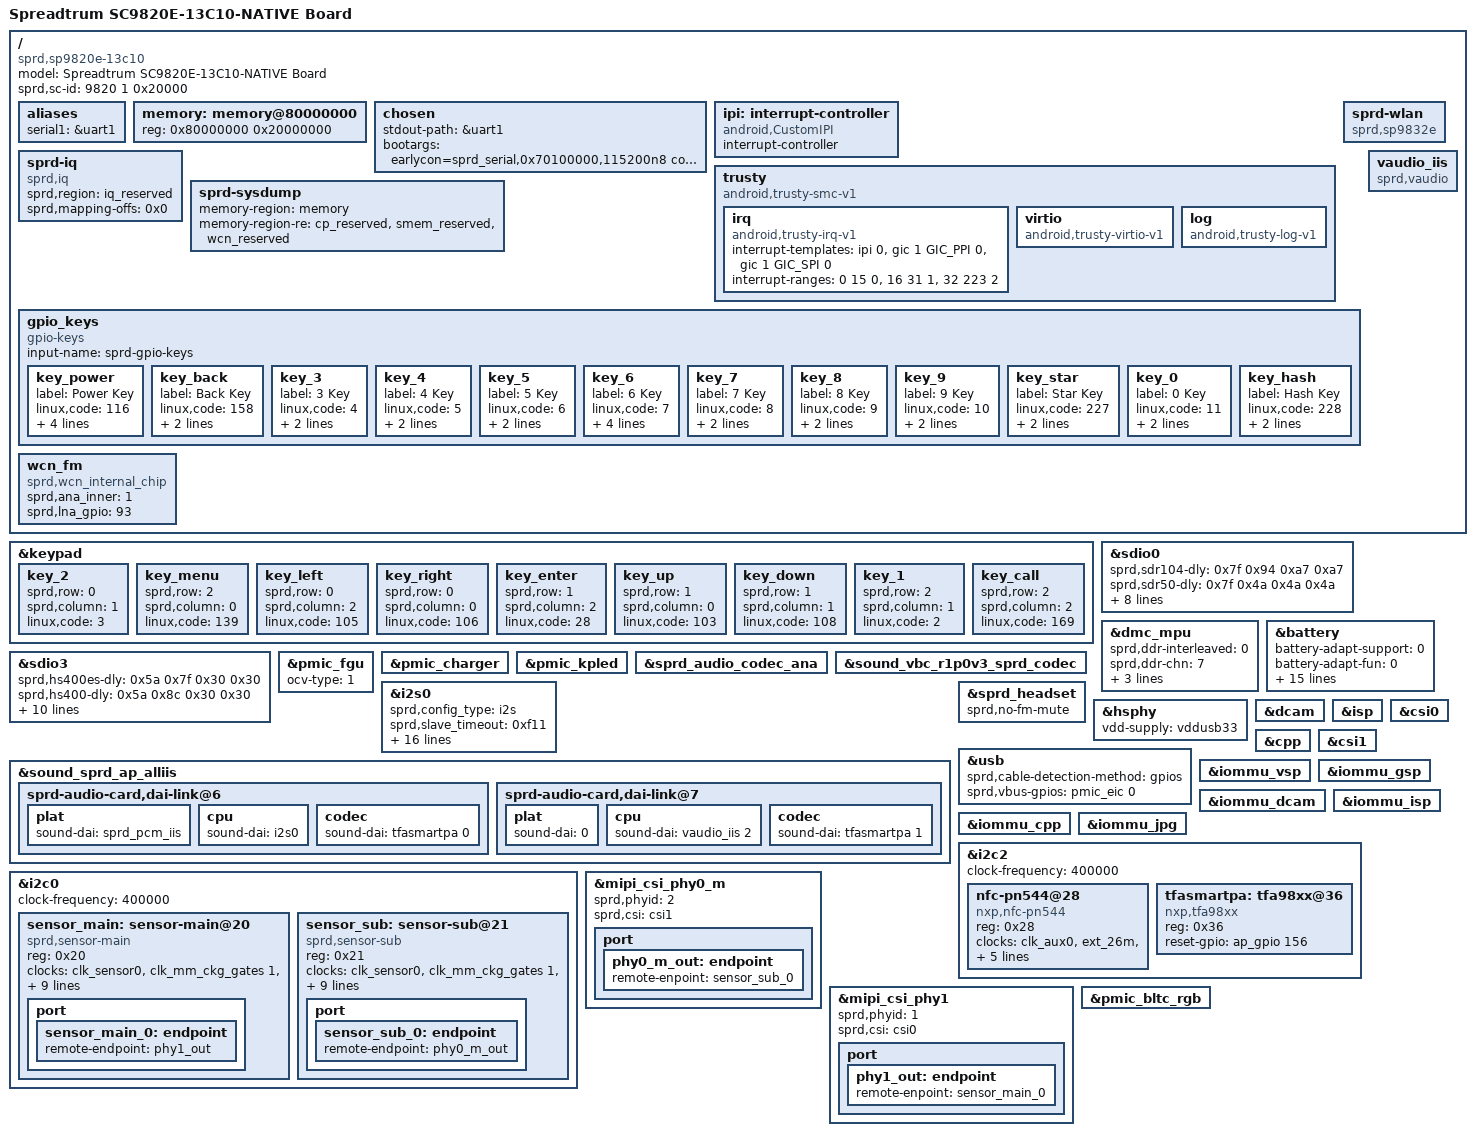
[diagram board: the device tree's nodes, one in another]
/*
 * Spreadtrum sharkle sp9820e board DTS file
 *
 * Copyright (C) 2017, Spreadtrum Communications Inc.
 *
 * This file is licensed under a dual GPLv2 or X11 license.
 */
/dts-v1/;

#include "sc9820e.dtsi"
#include "sp9820e-common.dtsi"

/ {
	model = "Spreadtrum SC9820E-13C10-NATIVE Board";

	compatible = "sprd,sp9820e-13c10", "sprd,sc9820e";

	sprd,sc-id = <9820 1 0x20000>;

	aliases {
		serial1 = &uart1;
	};

	memory: memory@80000000 {
		device_type = "memory";
		reg = <0x80000000 0x20000000>;
	};

	chosen {
		stdout-path = &uart1;
		bootargs = "earlycon=sprd_serial,0x70100000,115200n8 console=ttyS1,115200n8 loglevel=1 init=/init root=/dev/ram0 rw androidboot.hardware=sp9820e_13c10";
	};

	ipi: interrupt-controller {
		compatible = "android,CustomIPI";
		#interrupt-cells = <1>;
		interrupt-controller;
	};

	trusty {
		compatible = "android,trusty-smc-v1";

		irq {
			compatible = "android,trusty-irq-v1";
			interrupt-templates = <&ipi 0>,
						<&gic 1 GIC_PPI 0>,
						<&gic 1 GIC_SPI 0>;
			interrupt-ranges = < 0  15 0>,
						<16  31 1>,
						<32 223 2>;
		};

		virtio {
			compatible = "android,trusty-virtio-v1";
		};

		log {
			compatible = "android,trusty-log-v1";
		};
	};

	sprd-iq {
		compatible = "sprd,iq";
		sprd,region = <&iq_reserved>;
		sprd,mapping-offs = <0x0>;
	};

	sprd-sysdump {
		memory-region = <&memory>;
		memory-region-re = <&cp_reserved>, <&smem_reserved>,
				   <&wcn_reserved>;
	};

	sprd-wlan {
		 compatible = "sprd,sp9832e";
	};

	gpio_keys {
		compatible = "gpio-keys";
		input-name = "sprd-gpio-keys";
		status = "ok";

		key_power {
			label = "Power Key";
			linux,code = <116>;
			gpios = <&pmic_eic 1 1>;
			debounce-interval = <5>;
			gpio-key,wakeup;
			gpio-key,level-trigger;
		};
		key_back {
			label = "Back Key";
			linux,code = <158>;
			gpios = <&ap_gpio 32 1>;
			gpio-key,wakeup;
		};
		key_3 {
			label = "3 Key";
			linux,code = <4>;
			gpios = <&ap_gpio 91 1>;
			gpio-key,wakeup;
		};
		key_4 {
			label = "4 Key";
			linux,code = <5>;
			gpios = <&ap_gpio 92 1>;
			gpio-key,wakeup;
		};
		key_5 {
			label = "5 Key";
			linux,code = <6>;
			gpios = <&ap_gpio 144 1>;
			gpio-key,wakeup;
		};
		key_6 {
			label = "6 Key";
			linux,code = <7>;
			gpios = <&pmic_eic 10 0>;
			debounce-interval = <5>;
			gpio-key,wakeup;
			gpio-key,level-trigger;
		};
		key_7 {
			label = "7 Key";
			linux,code = <8>;
			gpios = <&ap_gpio 146 1>;
			gpio-key,wakeup;
		};
		key_8 {
			label = "8 Key";
			linux,code = <9>;
			gpios = <&ap_gpio 90 1>;
			gpio-key,wakeup;
		};
		key_9 {
			label = "9 Key";
			linux,code = <10>;
			gpios = <&ap_gpio 147 1>;
			gpio-key,wakeup;
		};
		key_star {
			label = "Star Key";
			linux,code = <227>;
			gpios = <&ap_gpio 88 1>;
			gpio-key,wakeup;
		};
		key_0 {
			label = "0 Key";
			linux,code = <11>;
			gpios = <&ap_gpio 85 1>;
			gpio-key,wakeup;
		};
		key_hash {
			label = "Hash Key";
			linux,code = <228>;
			gpios = <&ap_gpio 154 1>;
			gpio-key,wakeup;
		};
	};

	vaudio_iis: vaudio_iis {
		compatible = "sprd,vaudio";
		#sound-dai-cells = <1>;
	};

	wcn_fm {
			compatible = "sprd,wcn_internal_chip";
			sprd,ana_inner = <1>;
			sprd,lna_gpio = <93>;
	};
};

&keypad {
	status = "okay";
	key_2 {
		sprd,row = <0>;
		sprd,column = <1>;
		linux,code = <3>;
	};
	key_menu {
		sprd,row = <2>;
		sprd,column = <0>;
		linux,code = <139>;
	};
	key_left {
		sprd,row = <0>;
		sprd,column = <2>;
		linux,code = <105>;
	};
	key_right {
		sprd,row = <0>;
		sprd,column = <0>;
		linux,code = <106>;
	};
	key_enter {
		sprd,row = <1>;
		sprd,column = <2>;
		linux,code = <28>;
	};
	key_up {
		sprd,row = <1>;
		sprd,column = <0>;
		linux,code = <103>;
	};
	key_down {
		sprd,row = <1>;
		sprd,column = <1>;
		linux,code = <108>;
	};
	key_1 {
		sprd,row = <2>;
		sprd,column = <1>;
		linux,code = <2>;
	};
	key_call {
		sprd,row = <2>;
		sprd,column = <2>;
		linux,code = <169>;
	};
};

&sdio0 {
	sprd,sdr104-dly = <0x7f 0x94 0xa7 0xa7>;
	sprd,sdr50-dly = <0x7f 0x4a 0x4a 0x4a>;
	vmmc-supply = <&vddsdcore>;
	vqmmc-supply = <&vddsdio>;
	voltage-ranges = <3000 3000>;
	bus-width = <4>;
	sd-uhs-sdr50;
	sprd,name = "sdio_sd";
	no-sdio;
	no-mmc;
	status = "okay";
};

&dmc_mpu {
	sprd,ddr-interleaved = <0>;
	sprd,ddr-chn = <7>;
	chn-name = "MM", "GPU", "DISP",
		"A53", "AP/VSP/GSP", "WTLCP/PUBCP",
		"WCN/AON";
	memory-region = <&pub0_mpu_reserved>;
};

&sdio3 {
	sprd,hs400es-dly = <0x5a 0x7f 0x30 0x30>;
	sprd,hs400-dly = <0x5a 0x8c 0x30 0x30>;
	sprd,hs200-dly = <0x7f 0x8c 0x8e 0x8e>;
	sprd,ddr52-dly = <0x9f 0xB3 0x1e 0x1e>;
	vmmc-supply = <&vddemmccore>;
	voltage-ranges = <3000 3000>;
	bus-width = <8>;
	non-removable;
	cap-mmc-hw-reset;
	sprd,name = "sdio_emmc";
	no-sdio;
	no-sd;
	status = "okay";
};

&battery {
	battery-adapt-support = <0>;
	battery-adapt-fun = <0>;
	adp-cdp-cur = <450>;
	adp-dcp-cur = <700>;
	adp-sdp-cur = <450>;
	adp-unknown-cur = <450>;
	chg-end-vol = <4200>;
	chg-end-vol-check = <4180>;
	chg-bat-safety-vol = <4230>;
	rechg-vol = <4120>;
	rsense-real = <200>;
	rint = <206>;
	cnom = <1962>;
	ocv-tab-vol = <4172 4102 4055 4009 3973 3942 3912
			3885 3856 3822 3798 3784 3776 3772
			3768 3760 3742 3714 3666 3599 3400>;
	ocv-tab-cap = <100  95   90   85   80   75   70
			65   60   55   50   45   40   35
			30   25   20   15   10   5   0>;
};

&pmic_fgu {
	ocv-type = <1>;
};

&pmic_charger {
	status = "okay";
};

&pmic_kpled {
	 status = "okay";
};

&sprd_audio_codec_ana {
	status = "okay";
};

&sound_vbc_r1p0v3_sprd_codec {
	status = "okay";
};

&i2s0 {
	status = "okay";

	sprd,config_type = "i2s";
	sprd,slave_timeout = <0xf11>;
	sprd,_hw_port = <0>;
	sprd,fs = <48000>;
	sprd,bus_type = <0>;
	sprd,rtx_mode = <3>;
	sprd,byte_per_chan = <1>;
	sprd,slave_mode = <0>;
	sprd,lsb = <0>;
	sprd,lrck = <1>; /*sync_mode*/
	sprd,low_for_left = <0>; /*lrck_inv*/
	sprd,clk_inv = <1>;
	sprd,pcm_short_frame = <0>; /*pcm_bus_mode*/
	sprd,pcm_slot = <0x1>;
	sprd,pcm_cycle = <1>;
	sprd,tx_watermark = <16>;
	sprd,rx_watermark = <16>;
	sprd,i2s_compatible= <1>;
};

&sound_sprd_ap_alliis {
	status = "okay";
	sprd-audio-card,dai-link@6 {
		plat {
			sound-dai = <&sprd_pcm_iis>;
		};
		cpu {
			sound-dai = <&i2s0>;
		};
		codec {
			sound-dai = <&tfasmartpa 0>;
		};
	};
	sprd-audio-card,dai-link@7 {
		plat {
			sound-dai = <0>;
		};
		cpu {
			/* Voice through nxp smart pa(a dummy dai) */
			sound-dai = <&vaudio_iis 2>;
		};
		codec {
			sound-dai = <&tfasmartpa 1>;
		};
	};
};

&sprd_headset {
	status = "okay";
	sprd,no-fm-mute;
};

&hsphy {
	vdd-supply = <&vddusb33>;
};

&usb {
	sprd,cable-detection-method = "gpios";
	sprd,vbus-gpios = <&pmic_eic 0 0>;
};

&dcam {
	status = "okay";
};

&isp {
	status = "okay";
};

&csi0 {
	status = "okay";
};

&cpp {
	status = "okay";
};

&csi1 {
	status = "okay";
};

&iommu_vsp {
	status = "okay";
};
&iommu_gsp {
	status = "okay";
};

&iommu_dcam {
	status = "okay";
};

&iommu_isp {
	status = "okay";
};

&iommu_cpp {
	status = "okay";
};

&iommu_jpg {
	status = "okay";
};

&i2c0 {
	status = "okay";
	clock-frequency = <400000>;

	sensor_main: sensor-main@20 {
		compatible = "sprd,sensor-main";
		reg = <0x20>;
		clock-names = "clk_src","sensor_eb",
			"clk_96m","clk_76m8",
			"clk_48m","clk_26m";
		clocks = <&clk_sensor0>, <&clk_mm_ckg_gates 1>,
			<&clk_twpll_96m>,<&clk_twpll_76m8>,
			<&clk_twpll_48m>,<&ext_26m>;
		vddio-supply = <&vddcamio>;
		vddcama-supply = <&vddcama>;
		vddcamd-supply = <&vddcamd>;
		vddcammot-supply = <&vddcammot>;
		reset-gpios = <&ap_gpio 45 0>;
		power-down-gpios = <&ap_gpio 47 0>;
		host = "dcam0";
		port {
			sensor_main_0: endpoint {
				remote-endpoint = <&phy1_out>;
			};
		};
	};

	sensor_sub: sensor-sub@21 {
		compatible = "sprd,sensor-sub";
		reg = <0x21>;
		clock-names = "clk_src","sensor_eb",
			"clk_96m","clk_76m8",
			"clk_48m","clk_26m";
		clocks = <&clk_sensor0>, <&clk_mm_ckg_gates 1>,
			<&clk_twpll_96m>,<&clk_twpll_76m8>,
			<&clk_twpll_48m>,<&ext_26m>;
		vddio-supply = <&vddcamio>;
		vddcama-supply = <&vddcama>;
		vddcamd-supply = <&vddcamd>;
		vddcammot-supply = <&vddcammot>;
		reset-gpios = <&ap_gpio 44 0>;
		power-down-gpios = <&ap_gpio 46 0>;
		host = "dcam1";
		port {
			sensor_sub_0: endpoint {
				remote-endpoint = <&phy0_m_out>;
			};
		};
	};
};

&i2c2 {
	status = "okay";
	clock-frequency = <400000>;

	nfc-pn544@28 {
		compatible = "nxp,nfc-pn544";
		reg = <0x28>;
		clock-names = "nfc_clk","source","enable";
		clocks = <&clk_aux0>,<&ext_26m>,<&clk_aon_apb_gates1 2>;
		nxp,irq-gpio = <&ap_gpio 62 0>;
		nxp,ven-gpio = <&ap_gpio 9 0>;
		interrupt-names = "nfc_irq";
		nxp,firm-gpio = <&ap_gpio 7 0>;
		nxp,clkreq-gpio = <&ap_gpio 31 0>;
		status = "ok";
	};

	tfasmartpa:tfa98xx@36 {
		compatible = "nxp,tfa98xx";
		#sound-dai-cells = <1>;
		reg = <0x36>;
		reset-gpio= <&ap_gpio 156 0>;
	};
};

&mipi_csi_phy0_m {
	status = "okay";
	sprd,phyid = <2>;
	sprd,csi = <&csi1>;
	port {
	phy0_m_out: endpoint {
		remote-enpoint = <&sensor_sub_0>;
		};
	};
};

&mipi_csi_phy1 {
	status = "okay";
	sprd,phyid = <1>;
	sprd,csi = <&csi0>;
	port {
	phy1_out: endpoint {
		remote-enpoint = <&sensor_main_0>;
		};
	};
};

&pmic_bltc_rgb {
	status = "okay";
};
